VERSION ""

NS_ :

BS_:

BU_: Main_Module Torque_Vector Driveline Precharge Dashboard TESTER DAQ Precharge BMS1 TEST_NODE TEST_NODE_2 DAQ

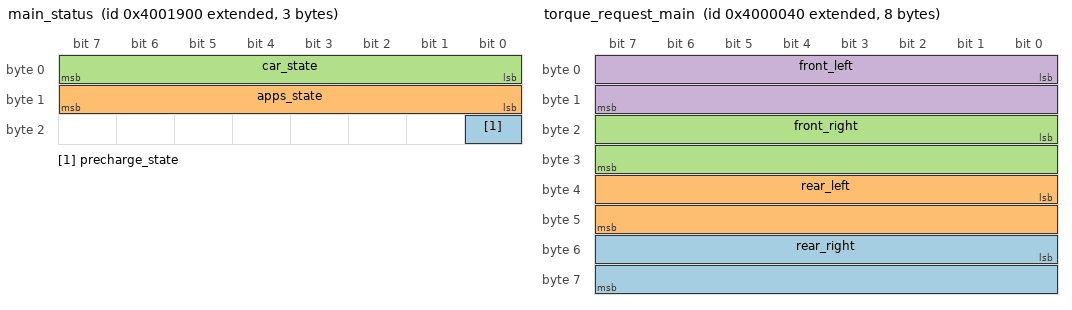
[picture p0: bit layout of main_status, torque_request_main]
BO_ 2214598912 main_status: 3 Main_Module
 SG_ precharge_state : 16|1@1+ (1,0) [0|0] "" Vector__XXX
 SG_ apps_state : 8|8@1+ (1,0) [0|0] "" Vector__XXX
 SG_ car_state : 0|8@1+ (1,0) [0|0] "" Vector__XXX

BO_ 2214592576 torque_request_main: 8 Main_Module
 SG_ rear_right : 48|16@1- (1,0) [0|0] "" Vector__XXX
 SG_ rear_left : 32|16@1- (1,0) [0|0] "" Vector__XXX
 SG_ front_right : 16|16@1- (1,0) [0|0] "" Vector__XXX
 SG_ front_left : 0|16@1- (1,0) [0|0] "" Vector__XXX

BO_ 2550136768 daq_response_MAIN_MODULE: 8 Main_Module
 SG_ daq_response : 0|64@1+ (1,0) [0|0] "" Vector__XXX

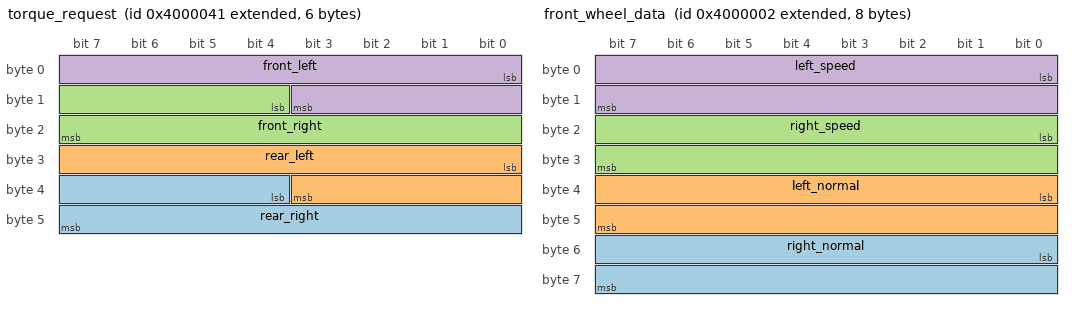
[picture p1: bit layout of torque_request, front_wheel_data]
BO_ 2214592577 torque_request: 6 Torque_Vector
 SG_ rear_right : 36|12@1+ (1,0) [0|0] "" Vector__XXX
 SG_ rear_left : 24|12@1+ (1,0) [0|0] "" Vector__XXX
 SG_ front_right : 12|12@1+ (1,0) [0|0] "" Vector__XXX
 SG_ front_left : 0|12@1+ (1,0) [0|0] "" Vector__XXX

BO_ 2147490049 bitstream_flash_status: 1 Torque_Vector
 SG_ flash_timeout_rx : 1|1@1+ (1,0) [0|0] "" Vector__XXX
 SG_ flash_success : 0|1@1+ (1,0) [0|0] "" Vector__XXX

BO_ 2214598914 front_driveline_hb: 2 Driveline
 SG_ front_right_motor : 8|8@1+ (1,0) [0|0] "" Vector__XXX
 SG_ front_left_motor : 0|8@1+ (1,0) [0|0] "" Vector__XXX

BO_ 2214598978 rear_driveline_hb: 2 Driveline
 SG_ back_right_motor : 8|8@1+ (1,0) [0|0] "" Vector__XXX
 SG_ back_left_motor : 0|8@1+ (1,0) [0|0] "" Vector__XXX

BO_ 2214592514 front_wheel_data: 8 Driveline
 SG_ right_normal : 48|16@1+ (1,0) [0|0] "" Vector__XXX
 SG_ left_normal : 32|16@1+ (1,0) [0|0] "" Vector__XXX
 SG_ right_speed : 16|16@1+ (1,0) [0|0] "" Vector__XXX
 SG_ left_speed : 0|16@1+ (1,0) [0|0] "" Vector__XXX

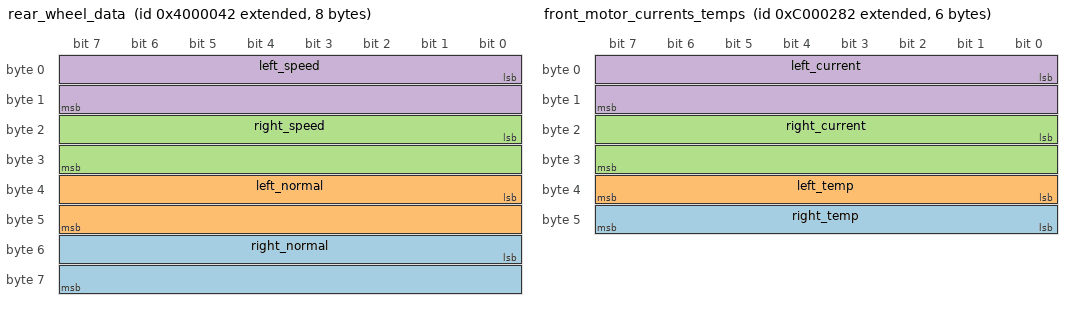
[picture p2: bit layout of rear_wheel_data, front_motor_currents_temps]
BO_ 2214592578 rear_wheel_data: 8 Driveline
 SG_ right_normal : 48|16@1+ (1,0) [0|0] "" Vector__XXX
 SG_ left_normal : 32|16@1+ (1,0) [0|0] "" Vector__XXX
 SG_ right_speed : 16|16@1+ (1,0) [0|0] "" Vector__XXX
 SG_ left_speed : 0|16@1+ (1,0) [0|0] "" Vector__XXX

BO_ 2348810882 front_motor_currents_temps: 6 Driveline
 SG_ right_temp : 40|8@1+ (1,0) [0|0] "C" Vector__XXX
 SG_ left_temp : 32|8@1+ (1,0) [0|0] "C" Vector__XXX
 SG_ right_current : 16|16@1+ (1,0) [0|0] "" Vector__XXX
 SG_ left_current : 0|16@1+ (1,0) [0|0] "" Vector__XXX

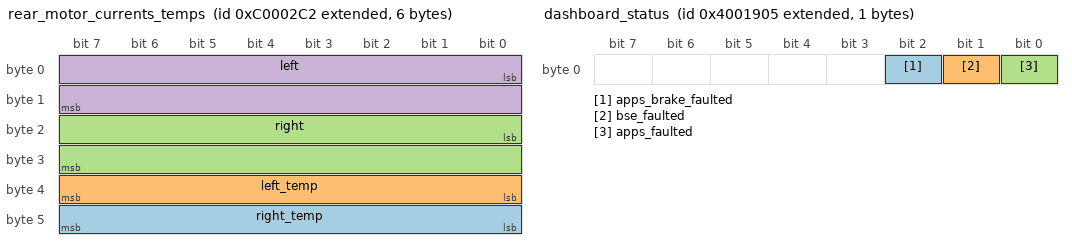
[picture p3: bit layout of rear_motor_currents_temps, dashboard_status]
BO_ 2348810946 rear_motor_currents_temps: 6 Driveline
 SG_ right_temp : 40|8@1+ (1,0) [0|0] "C" Vector__XXX
 SG_ left_temp : 32|8@1+ (1,0) [0|0] "C" Vector__XXX
 SG_ right : 16|16@1+ (1,0) [0|0] "" Vector__XXX
 SG_ left : 0|16@1+ (1,0) [0|0] "" Vector__XXX

BO_ 2281734148 test_precharge_msg: 1 Precharge
 SG_ test_precharge_sig : 0|8@1+ (1,0) [0|0] "" Vector__XXX

BO_ 2483028613 raw_throttle_brake: 3 Dashboard
 SG_ brake : 12|12@1+ (1,0) [0|0] "" Vector__XXX
 SG_ throttle : 0|12@1+ (1,0) [0|0] "" Vector__XXX

BO_ 2214592517 start_button: 1 Dashboard
 SG_ start : 0|1@1+ (1,0) [0|0] "" Vector__XXX

BO_ 2214598917 dashboard_status: 1 Dashboard
 SG_ apps_brake_faulted : 2|1@1+ (1,0) [0|0] "" Vector__XXX
 SG_ bse_faulted : 1|1@1+ (1,0) [0|0] "" Vector__XXX
 SG_ apps_faulted : 0|1@1+ (1,0) [0|0] "" Vector__XXX

BO_ 2550136773 daq_response_DASHBOARD: 8 Dashboard
 SG_ daq_response : 0|64@1+ (1,0) [0|0] "" Vector__XXX

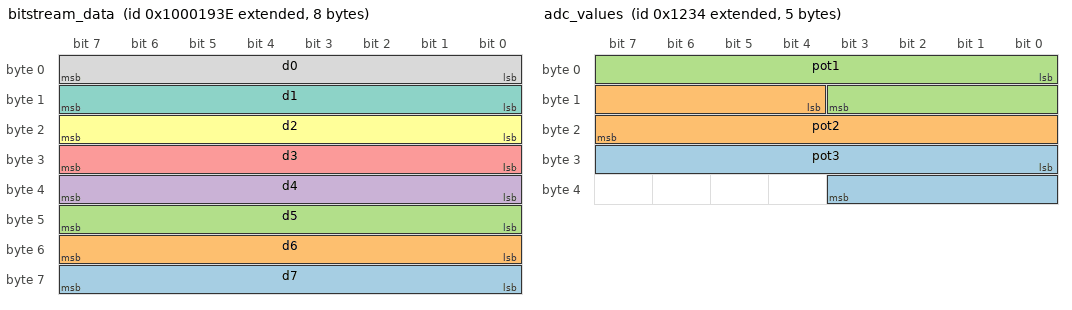
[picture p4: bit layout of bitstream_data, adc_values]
BO_ 2415925566 bitstream_data: 8 TESTER
 SG_ d7 : 56|8@1+ (1,0) [0|0] "" Vector__XXX
 SG_ d6 : 48|8@1+ (1,0) [0|0] "" Vector__XXX
 SG_ d5 : 40|8@1+ (1,0) [0|0] "" Vector__XXX
 SG_ d4 : 32|8@1+ (1,0) [0|0] "" Vector__XXX
 SG_ d3 : 24|8@1+ (1,0) [0|0] "" Vector__XXX
 SG_ d2 : 16|8@1+ (1,0) [0|0] "" Vector__XXX
 SG_ d1 : 8|8@1+ (1,0) [0|0] "" Vector__XXX
 SG_ d0 : 0|8@1+ (1,0) [0|0] "" Vector__XXX

BO_ 2415925630 bitstream_request: 5 TESTER
 SG_ download_size : 1|32@1+ (1,0) [0|0] "" Vector__XXX
 SG_ download_request : 0|1@1+ (1,0) [0|0] "" Vector__XXX

BO_ 2483028018 daq_command_MAIN_MODULE: 8 DAQ
 SG_ daq_command : 0|64@1+ (1,0) [0|0] "" Vector__XXX

BO_ 2483028338 daq_command_DASHBOARD: 8 DAQ
 SG_ daq_command : 0|64@1+ (1,0) [0|0] "" Vector__XXX

BO_ 2214624554 balance_request: 2 Precharge
 SG_ volts : 0|16@1+ (1,0) [0|0] "" Vector__XXX

BO_ 2214624555 soc1: 2 BMS1
 SG_ soc : 0|16@1+ (1,0) [0|0] "" Vector__XXX

BO_ 2483028095 test_msg: 2 TEST_NODE
 SG_ test_sig : 0|16@1- (1,0) [0|0] "" Vector__XXX

BO_ 2483028159 test_msg2: 2 TEST_NODE
 SG_ test_sig2 : 0|16@1+ (1,0) [0|0] "" Vector__XXX

BO_ 2483028223 test_msg3: 2 TEST_NODE
 SG_ test_sig3 : 0|16@1+ (1,0) [0|0] "" Vector__XXX

BO_ 2483028287 test_msg4: 2 TEST_NODE
 SG_ test_sig4 : 0|16@1+ (1,0) [0|0] "" Vector__XXX

BO_ 2483028351 test_msg5: 2 TEST_NODE
 SG_ test_sig5 : 0|16@1+ (1,0) [0|0] "" Vector__XXX

BO_ 2348810751 wheel_speeds: 8 TEST_NODE
 SG_ right_speed : 32|32@1- (1,0) [0|0] "kph" Vector__XXX
 SG_ left_speed : 0|32@1- (1,0) [0|0] "kph" Vector__XXX

BO_ 2147488308 adc_values: 5 TEST_NODE
 SG_ pot3 : 24|12@1+ (1,0) [0|0] "" Vector__XXX
 SG_ pot2 : 12|12@1+ (1,0) [0|0] "" Vector__XXX
 SG_ pot1 : 0|12@1+ (1,0) [0|0] "" Vector__XXX

BO_ 2347693088 car_state: 1 TEST_NODE
 SG_ car_state : 0|8@1+ (1,0) [0|0] "" Vector__XXX

BO_ 2550136831 daq_response_TEST_NODE: 8 TEST_NODE
 SG_ daq_response : 0|64@1+ (1,0) [0|0] "" Vector__XXX

BO_ 2483028093 test_msg_2: 2 TEST_NODE_2
 SG_ test_sig : 0|16@1+ (1,0) [0|0] "" Vector__XXX

BO_ 2483028157 test_msg2_2: 2 TEST_NODE_2
 SG_ test_sig2 : 0|16@1+ (1,0) [0|0] "" Vector__XXX

BO_ 2483028221 test_msg3_2: 2 TEST_NODE_2
 SG_ test_sig3 : 0|16@1+ (1,0) [0|0] "" Vector__XXX

BO_ 2483028285 test_msg4_2: 2 TEST_NODE_2
 SG_ test_sig4 : 0|16@1+ (1,0) [0|0] "" Vector__XXX

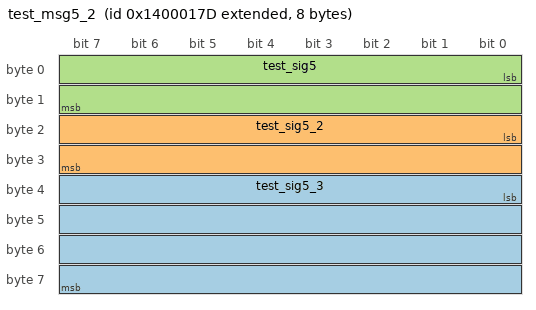
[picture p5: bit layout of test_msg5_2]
BO_ 2483028349 test_msg5_2: 8 TEST_NODE_2
 SG_ test_sig5_3 : 32|32@1- (1,0) [0|0] "" Vector__XXX
 SG_ test_sig5_2 : 16|16@1- (1,0) [0|0] "" Vector__XXX
 SG_ test_sig5 : 0|16@1+ (1,0) [0|0] "" Vector__XXX

BO_ 2147492386 test_stale: 1 TEST_NODE_2
 SG_ data : 0|8@1+ (1,0) [0|0] "" Vector__XXX

BO_ 2347693089 car_state2: 1 TEST_NODE_2
 SG_ car_state2 : 0|8@1+ (1,0) [0|0] "" Vector__XXX

BO_ 2550136829 daq_response_TEST_NODE_2: 8 TEST_NODE_2
 SG_ daq_response : 0|64@1+ (1,0) [0|0] "" Vector__XXX

BO_ 2483032050 daq_command_TEST_NODE: 8 DAQ
 SG_ daq_command : 0|64@1+ (1,0) [0|0] "" Vector__XXX

BO_ 2483031922 daq_command_TEST_NODE_2: 8 DAQ
 SG_ daq_command : 0|64@1+ (1,0) [0|0] "" Vector__XXX

CM_ BO_ 2214598912 "Status message for main module";
CM_ SG_ 2214598912 precharge_state "Precharge complete state";
CM_ SG_ 2214598912 apps_state "Accelerator plausibility state";
CM_ SG_ 2214598912 car_state "Main car state";
CM_ BO_ 2214592576 "Torque request for all motors, temporarily from main.";
CM_ SG_ 2214592576 rear_right "torque request. -4095-4095";
CM_ SG_ 2214592576 rear_left "torque request. -4095-4095";
CM_ SG_ 2214592576 front_right "torque request. -4095-4095";
CM_ SG_ 2214592576 front_left "torque request. -4095-4095";
CM_ BO_ 2550136768 "daq response from node MAIN_MODULE";
CM_ BO_ 2214592577 "Torque request for all motors.";
CM_ SG_ 2214592577 rear_right "torque request. 0-4096";
CM_ SG_ 2214592577 rear_left "torque request. 0-4096";
CM_ SG_ 2214592577 front_right "torque request. 0-4096";
CM_ SG_ 2214592577 front_left "torque request. 0-4096";
CM_ BO_ 2147490049 "Status message for bitstream flashing";
CM_ SG_ 2147490049 flash_timeout_rx "Timeout from CAN rx";
CM_ SG_ 2147490049 flash_success "Done flashing bitstream";
CM_ BO_ 2214598914 "front drivline heart beat";
CM_ BO_ 2214598978 "rear drivline heart beat";
CM_ BO_ 2214592514 "Wheel data for the rear tires";
CM_ BO_ 2214592578 "Wheel data for the rear tires";
CM_ BO_ 2348810882 "DC Current and Temperature of the motor controllers";
CM_ BO_ 2348810946 "DC Current and Temperature of the motor controllers";
CM_ BO_ 2281734148 "test precharge desc";
CM_ BO_ 2483028613 "throttle_brake desc";
CM_ BO_ 2214592517 "Car start button pressed";
CM_ BO_ 2214598917 "periodic dashboard heartbeat";
CM_ BO_ 2550136773 "daq response from node DASHBOARD";
CM_ BO_ 2415925566 "Bitstream download command";
CM_ SG_ 2415925566 d7 "Bitstream data word 7";
CM_ SG_ 2415925566 d6 "Bitstream data word 6";
CM_ SG_ 2415925566 d5 "Bitstream data word 5";
CM_ SG_ 2415925566 d4 "Bitstream data word 4";
CM_ SG_ 2415925566 d3 "Bitstream data word 3";
CM_ SG_ 2415925566 d2 "Bitstream data word 2";
CM_ SG_ 2415925566 d1 "Bitstream data word 1";
CM_ SG_ 2415925566 d0 "Bitstream data word 0";
CM_ BO_ 2415925630 "Bitstream state command";
CM_ SG_ 2415925630 download_size "size for expected bitstream download (bytes)";
CM_ SG_ 2415925630 download_request "Request to download new bitstream";
CM_ BO_ 2483028018 "daq command for node MAIN_MODULE";
CM_ BO_ 2483028338 "daq command for node DASHBOARD";
CM_ BO_ 2214624554 "Request BMSs to discharge their cells to the desired voltage";
CM_ BO_ 2214624555 "Estimated soc";
CM_ BO_ 2483028095 "test_msg desc";
CM_ BO_ 2483028159 "test_msg2 desc";
CM_ BO_ 2483028223 "test_msg2 desc";
CM_ BO_ 2483028287 "test_msg4 desc";
CM_ BO_ 2483028351 "test_msg5 desc";
CM_ BO_ 2348810751 "wheel speeds";
CM_ BO_ 2147488308 "adc potentiometer readings";
CM_ BO_ 2347693088 "state of the car";
CM_ BO_ 2550136831 "daq response from node TEST_NODE";
CM_ BO_ 2483028093 "test_msg desc";
CM_ BO_ 2483028157 "test_msg2 desc";
CM_ BO_ 2483028221 "test_msg2 desc";
CM_ BO_ 2483028285 "test_msg4 desc";
CM_ BO_ 2483028349 "test_msg5 desc";
CM_ BO_ 2147492386 "used to test stale";
CM_ BO_ 2347693089 "state of the car";
CM_ BO_ 2550136829 "daq response from node TEST_NODE_2";
CM_ BO_ 2483032050 "daq command for node TEST_NODE";
CM_ BO_ 2483031922 "daq command for node TEST_NODE_2";

VAL_ 2214598912 car_state 0 "init" 1 "precharging" 2 "buzzing" 3 "ready2drive" 4 "error" 5 "reset" 6 "recover" ;
VAL_ 2214598914 front_right_motor 0 "disconnected" 1 "setting_params" 2 "connected" 3 "error" ;
VAL_ 2214598914 front_left_motor 0 "disconnected" 1 "setting_params" 2 "connected" 3 "error" ;
VAL_ 2214598978 back_right_motor 0 "disconnected" 1 "setting_params" 2 "connected" 3 "error" ;
VAL_ 2214598978 back_left_motor 0 "disconnected" 1 "setting_params" 2 "connected" 3 "error" ;
VAL_ 2347693088 car_state 0 "ready2go" 1 "flipped" 2 "flying" 3 "lightspeed" ;
VAL_ 2347693089 car_state2 0 "ready2go" 1 "flipped" 2 "flying" 3 "lightspeed" ;
SIG_VALTYPE_ 2348810751 left_speed : 1;
SIG_VALTYPE_ 2348810751 right_speed : 1;
SIG_VALTYPE_ 2483028349 test_sig5_3 : 1;
